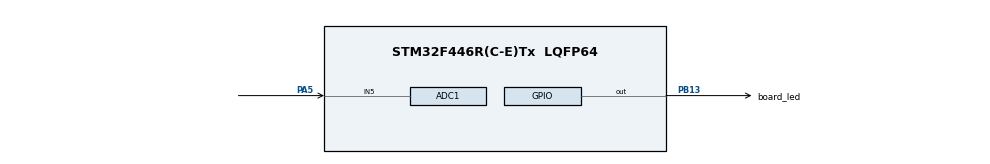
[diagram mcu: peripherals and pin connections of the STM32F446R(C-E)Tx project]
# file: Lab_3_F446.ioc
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ADC1.Channel-1\#ChannelRegularConversion=ADC_CHANNEL_5
ADC1.NbrOfConversionFlag=1
ADC1.Rank-1\#ChannelRegularConversion=1
ADC1.SamplingTime-1\#ChannelRegularConversion=ADC_SAMPLETIME_3CYCLES
ADC1.master=1
Mcu.Family=STM32F4
Mcu.Name=STM32F446R(C-E)Tx
Mcu.Package=LQFP64
NVIC.ADC_IRQn=true\:0\:0\:false\:false\:true\:true\:true\:true
NVIC.PriorityGroup=NVIC_PRIORITYGROUP_4
NVIC.TIM1_UP_TIM10_IRQn=true\:0\:0\:false\:false\:true\:true\:true\:true
NVIC.TIM2_IRQn=true\:0\:0\:false\:false\:true\:true\:true\:true
PA5.Signal=ADCx_IN5
PB13.GPIO_Label=board_led
PB13.Signal=GPIO_Output
PH0-OSC_IN.Mode=HSE-External-Oscillator
PH0-OSC_IN.Signal=RCC_OSC_IN
PH1-OSC_OUT.Mode=HSE-External-Oscillator
PH1-OSC_OUT.Signal=RCC_OSC_OUT
ProjectManager.HeapSize=0x200
ProjectManager.StackSize=0x400
ProjectManager.TargetToolchain=STM32CubeIDE
RCC.CortexFreq_Value=16000000
RCC.USBFreq_Value=96000000
RCC.VCOOutputFreq_Value=192000000
SH.ADCx_IN5.0=ADC1_IN5,IN5
TIM1.Channel-PWM\ Generation1\ No\ Output=TIM_CHANNEL_1
TIM1.Period=20
TIM1.Prescaler=40000
TIM2.Channel-PWM\ Generation1\ No\ Output=TIM_CHANNEL_1
TIM2.Period=200
TIM2.Prescaler=40000
VP_TIM1_VS_no_output1.Mode=PWM Generation1 No Output
VP_TIM2_VS_no_output1.Mode=PWM Generation1 No Output
board=custom

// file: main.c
/* USER CODE BEGIN Header */
/**
  ******************************************************************************
  * @file           : main.c
  * @brief          : Main program body
  ******************************************************************************
  * @attention
  *
  * Copyright (c) 2023 STMicroelectronics.
  * All rights reserved.
  *
  * This software is licensed under terms that can be found in the LICENSE file
  * in the root directory of this software component.
  * If no LICENSE file comes with this software, it is provided AS-IS.
  *
  ******************************************************************************
  */
/* USER CODE END Header */
#include <stdint.h>
#include "main.h"

/* USER CODE BEGIN PD */
#define median_number 50
#define WINDOW_SIZE 300
/* USER CODE END PD */

 ADC_HandleTypeDef hadc1;

TIM_HandleTypeDef htim1;
TIM_HandleTypeDef htim2;

/* USER CODE BEGIN PV */
extern volatile int16_t adc_reg_val;
int16_t filtered_adc_val = 0;
int16_t adc_val = 0;
/* USER CODE END PV */

void SystemClock_Config(void);
static void MX_GPIO_Init(void);
static void MX_ADC1_Init(void);
static void MX_TIM2_Init(void);
static void MX_TIM1_Init(void);

/* USER CODE BEGIN 0 */

int16_t normalize(int16_t number) {
	int16_t old_min = 0, old_max = 4095;
	int16_t min = -1000, max = 1000;
	number = ((number - old_min) * (max - min) / (old_max - old_min)) + min;
	return number;
}

int16_t compare(const void *a, const void *b) {
	return *(int16_t*)a - *(int16_t*)b;
}

int16_t median_filter(int16_t num) {
	static int16_t arr[median_number] = {0};
	static int16_t ind = 0;
	arr[ind] = num;
	ind = (ind + 1) % median_number;

	int16_t temp_arr[median_number] = {0};
	for (int16_t i = 0; i < median_number; i++) {
		temp_arr[i] = arr[i];
	}

	qsort(temp_arr, median_number, sizeof(int16_t), compare);

	return temp_arr[median_number / 2];
}

int16_t median_filter_x2(int16_t num) {
	static int16_t arr[median_number * 2] = {0};
	static int16_t ind = 0;
	arr[ind] = num;
	ind = (ind + 1) % (median_number * 2);

	int16_t temp_arr[median_number * 2] = {0};
	for (int16_t i = 0; i < median_number * 2; i++) {
		temp_arr[i] = arr[i];
	}

	qsort(temp_arr, median_number * 2, sizeof(int16_t), compare);

	return temp_arr[median_number];
}

int16_t least_squares_filter(int16_t input) {

  static int16_t window[WINDOW_SIZE] = {0};

  // y = ax + b
  float a = 0;
  float b = 0;
  float sumX = 0;
  float sumY = 0;
  float sumX2 = 0;
  float sumXY = 0;

  for(int16_t i = 0; i < WINDOW_SIZE - 1; i++) {
    window[i] = window[i + 1];
  }
  window[WINDOW_SIZE - 1] = input;

  for(int16_t i = 0; i < WINDOW_SIZE; i++) {
    sumX += i;
    sumY += window[i];
    sumX2 += i * i;
    sumXY += i * window[i];
  }
  sumX /= (float) WINDOW_SIZE;
  sumY /= (float) WINDOW_SIZE;
  sumX2 /= (float) WINDOW_SIZE;
  sumXY /= (float) WINDOW_SIZE;

  a = (float) (sumXY - sumX * sumY) / (sumX2 - sumX * sumX);
  b = (float) sumY - a * sumX;
  int16_t result = a * (WINDOW_SIZE - 1) + b;
  if (result < 0) {
    result = 0;
  }
  return result;
}

int16_t first_order_lag_filter(int16_t input) {
	float Tf = 0.3;
	float dt = 0.05;
	float k1 = Tf/(Tf+dt);
	float k2 = dt/(Tf+dt);
    static int16_t prevOut = 0;
    int16_t out = k1 * prevOut + k2 * input;
    prevOut = out;
  return out;
}

/* USER CODE END 0 */

int main(void)
{

  /* MCU Configuration--------------------------------------------------------*/

  /* Reset of all peripherals, Initializes the Flash interface and the Systick. */
  HAL_Init();

  /* Configure the system clock */
  SystemClock_Config();

  /* Initialize all configured peripherals */
  MX_GPIO_Init();
  MX_ADC1_Init();
  MX_TIM2_Init();
  MX_TIM1_Init();
  /* USER CODE BEGIN 2 */
  HAL_TIM_Base_Start_IT(&htim1);
  HAL_TIM_Base_Start_IT(&htim2);
  HAL_GPIO_WritePin(board_led_GPIO_Port, board_led_Pin, GPIO_PIN_RESET);
  /* USER CODE END 2 */

  /* Infinite loop */
  /* USER CODE BEGIN WHILE */
  while (1)
  {
	  filtered_adc_val = median_filter(adc_reg_val);
//	  filtered_adc_val = first_order_lag_filter(filtered_adc_val);
	  filtered_adc_val = least_squares_filter(filtered_adc_val);

	  adc_val = normalize((int16_t) filtered_adc_val);

	  if (adc_val > 700) {
		  TIM2->PSC = 20000;
	  }
	  else if(adc_val < -700) {
		  TIM2->PSC = 40000;
	  }
    /* USER CODE END WHILE */

  }
}

void SystemClock_Config(void)
{
  RCC_OscInitTypeDef RCC_OscInitStruct = {0};
  RCC_ClkInitTypeDef RCC_ClkInitStruct = {0};

  /** Configure the main internal regulator output voltage
  */
  __HAL_RCC_PWR_CLK_ENABLE();
  __HAL_PWR_VOLTAGESCALING_CONFIG(PWR_REGULATOR_VOLTAGE_SCALE3);

  /** Initializes the RCC Oscillators according to the specified parameters
  * in the RCC_OscInitTypeDef structure.
  */
  RCC_OscInitStruct.OscillatorType = RCC_OSCILLATORTYPE_HSI;
  RCC_OscInitStruct.HSIState = RCC_HSI_ON;
  RCC_OscInitStruct.HSICalibrationValue = RCC_HSICALIBRATION_DEFAULT;
  RCC_OscInitStruct.PLL.PLLState = RCC_PLL_NONE;
  if (HAL_RCC_OscConfig(&RCC_OscInitStruct) != HAL_OK)
  {
    Error_Handler();
  }

  /** Initializes the CPU, AHB and APB buses clocks
  */
  RCC_ClkInitStruct.ClockType = RCC_CLOCKTYPE_HCLK|RCC_CLOCKTYPE_SYSCLK
                              |RCC_CLOCKTYPE_PCLK1|RCC_CLOCKTYPE_PCLK2;
  RCC_ClkInitStruct.SYSCLKSource = RCC_SYSCLKSOURCE_HSI;
  RCC_ClkInitStruct.AHBCLKDivider = RCC_SYSCLK_DIV1;
  RCC_ClkInitStruct.APB1CLKDivider = RCC_HCLK_DIV1;
  RCC_ClkInitStruct.APB2CLKDivider = RCC_HCLK_DIV1;

  if (HAL_RCC_ClockConfig(&RCC_ClkInitStruct, FLASH_LATENCY_0) != HAL_OK)
  {
    Error_Handler();
  }
}

static void MX_ADC1_Init(void)
{

  ADC_ChannelConfTypeDef sConfig = {0};

  /** Configure the global features of the ADC (Clock, Resolution, Data Alignment and number of conversion)
  */
  hadc1.Instance = ADC1;
  hadc1.Init.ClockPrescaler = ADC_CLOCK_SYNC_PCLK_DIV2;
  hadc1.Init.Resolution = ADC_RESOLUTION_12B;
  hadc1.Init.ScanConvMode = DISABLE;
  hadc1.Init.ContinuousConvMode = DISABLE;
  hadc1.Init.DiscontinuousConvMode = DISABLE;
  hadc1.Init.ExternalTrigConvEdge = ADC_EXTERNALTRIGCONVEDGE_NONE;
  hadc1.Init.ExternalTrigConv = ADC_SOFTWARE_START;
  hadc1.Init.DataAlign = ADC_DATAALIGN_RIGHT;
  hadc1.Init.NbrOfConversion = 1;
  hadc1.Init.DMAContinuousRequests = DISABLE;
  hadc1.Init.EOCSelection = ADC_EOC_SINGLE_CONV;
  if (HAL_ADC_Init(&hadc1) != HAL_OK)
  {
    Error_Handler();
  }

  /** Configure for the selected ADC regular channel its corresponding rank in the sequencer and its sample time.
  */
  sConfig.Channel = ADC_CHANNEL_5;
  sConfig.Rank = 1;
  sConfig.SamplingTime = ADC_SAMPLETIME_3CYCLES;
  if (HAL_ADC_ConfigChannel(&hadc1, &sConfig) != HAL_OK)
  {
    Error_Handler();
  }

}

static void MX_TIM1_Init(void)
{

  TIM_MasterConfigTypeDef sMasterConfig = {0};
  TIM_OC_InitTypeDef sConfigOC = {0};
  TIM_BreakDeadTimeConfigTypeDef sBreakDeadTimeConfig = {0};

  htim1.Instance = TIM1;
  htim1.Init.Prescaler = 40000;
  htim1.Init.CounterMode = TIM_COUNTERMODE_UP;
  htim1.Init.Period = 20;
  htim1.Init.ClockDivision = TIM_CLOCKDIVISION_DIV1;
  htim1.Init.RepetitionCounter = 0;
  htim1.Init.AutoReloadPreload = TIM_AUTORELOAD_PRELOAD_DISABLE;
  if (HAL_TIM_PWM_Init(&htim1) != HAL_OK)
  {
    Error_Handler();
  }
  sMasterConfig.MasterOutputTrigger = TIM_TRGO_RESET;
  sMasterConfig.MasterSlaveMode = TIM_MASTERSLAVEMODE_DISABLE;
  if (HAL_TIMEx_MasterConfigSynchronization(&htim1, &sMasterConfig) != HAL_OK)
  {
    Error_Handler();
  }
  sConfigOC.OCMode = TIM_OCMODE_PWM1;
  sConfigOC.Pulse = 0;
  sConfigOC.OCPolarity = TIM_OCPOLARITY_HIGH;
  sConfigOC.OCNPolarity = TIM_OCNPOLARITY_HIGH;
  sConfigOC.OCFastMode = TIM_OCFAST_DISABLE;
  sConfigOC.OCIdleState = TIM_OCIDLESTATE_RESET;
  sConfigOC.OCNIdleState = TIM_OCNIDLESTATE_RESET;
  if (HAL_TIM_PWM_ConfigChannel(&htim1, &sConfigOC, TIM_CHANNEL_1) != HAL_OK)
  {
    Error_Handler();
  }
  sBreakDeadTimeConfig.OffStateRunMode = TIM_OSSR_DISABLE;
  sBreakDeadTimeConfig.OffStateIDLEMode = TIM_OSSI_DISABLE;
  sBreakDeadTimeConfig.LockLevel = TIM_LOCKLEVEL_OFF;
  sBreakDeadTimeConfig.DeadTime = 0;
  sBreakDeadTimeConfig.BreakState = TIM_BREAK_DISABLE;
  sBreakDeadTimeConfig.BreakPolarity = TIM_BREAKPOLARITY_HIGH;
  sBreakDeadTimeConfig.AutomaticOutput = TIM_AUTOMATICOUTPUT_DISABLE;
  if (HAL_TIMEx_ConfigBreakDeadTime(&htim1, &sBreakDeadTimeConfig) != HAL_OK)
  {
    Error_Handler();
  }

}

static void MX_TIM2_Init(void)
{

  TIM_MasterConfigTypeDef sMasterConfig = {0};
  TIM_OC_InitTypeDef sConfigOC = {0};

  htim2.Instance = TIM2;
  htim2.Init.Prescaler = 40000;
  htim2.Init.CounterMode = TIM_COUNTERMODE_UP;
  htim2.Init.Period = 200;
  htim2.Init.ClockDivision = TIM_CLOCKDIVISION_DIV1;
  htim2.Init.AutoReloadPreload = TIM_AUTORELOAD_PRELOAD_DISABLE;
  if (HAL_TIM_PWM_Init(&htim2) != HAL_OK)
  {
    Error_Handler();
  }
  sMasterConfig.MasterOutputTrigger = TIM_TRGO_RESET;
  sMasterConfig.MasterSlaveMode = TIM_MASTERSLAVEMODE_DISABLE;
  if (HAL_TIMEx_MasterConfigSynchronization(&htim2, &sMasterConfig) != HAL_OK)
  {
    Error_Handler();
  }
  sConfigOC.OCMode = TIM_OCMODE_PWM1;
  sConfigOC.Pulse = 0;
  sConfigOC.OCPolarity = TIM_OCPOLARITY_HIGH;
  sConfigOC.OCFastMode = TIM_OCFAST_DISABLE;
  if (HAL_TIM_PWM_ConfigChannel(&htim2, &sConfigOC, TIM_CHANNEL_1) != HAL_OK)
  {
    Error_Handler();
  }

}

static void MX_GPIO_Init(void)
{
  GPIO_InitTypeDef GPIO_InitStruct = {0};

  /* GPIO Ports Clock Enable */
  __HAL_RCC_GPIOH_CLK_ENABLE();
  __HAL_RCC_GPIOA_CLK_ENABLE();
  __HAL_RCC_GPIOB_CLK_ENABLE();

  /*Configure GPIO pin Output Level */
  HAL_GPIO_WritePin(board_led_GPIO_Port, board_led_Pin, GPIO_PIN_RESET);

  /*Configure GPIO pin : board_led_Pin */
  GPIO_InitStruct.Pin = board_led_Pin;
  GPIO_InitStruct.Mode = GPIO_MODE_OUTPUT_PP;
  GPIO_InitStruct.Pull = GPIO_NOPULL;
  GPIO_InitStruct.Speed = GPIO_SPEED_FREQ_LOW;
  HAL_GPIO_Init(board_led_GPIO_Port, &GPIO_InitStruct);

}

void Error_Handler(void)
{
  __disable_irq();
  while (1)
  {
  }
}
